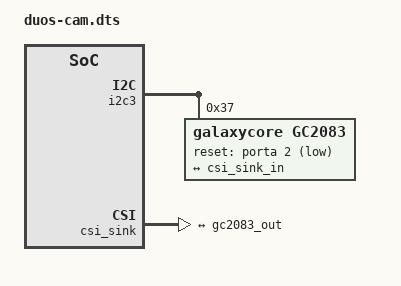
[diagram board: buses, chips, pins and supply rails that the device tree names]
/*
 * GC2083 on J1 of a Milk-V Duo S.
 *
 * Numeric constants rather than dt-bindings macros because neither dtc nor
 * armbian-add-overlay runs the C preprocessor:
 *   147 = CLK_CAM0        (include/dt-bindings/clock/sophgo,cv1800.h)
 *     1 = GPIO_ACTIVE_LOW (include/dt-bindings/gpio/gpio.h)
 * Both are ABI, so this is ugly rather than fragile.
 *
 * The cell counts are not decoration: a fragment has no parent context, so
 * without them dtc reads reg = <0x37> against the default #address-cells = <2>
 * and warns that it is the wrong length.
 *
 * There is no CSI-2 receiver driver for the SG2000, but the endpoint still
 * cannot dangle: fwnode_graph_get_endpoint_by_id() skips any endpoint whose
 * remote is unavailable, and a missing remote counts as unavailable, so the
 * driver would report "missing endpoint node". Hence csi-sink below, which is
 * the far end of the link. duos-cam-stub.ko binds to it and does nothing with
 * the lanes; its only job is to call v4l2_device_register_subdev_nodes() so
 * that /dev/v4l-subdev0 exists. Without that module loaded the node is inert
 * and the sensor still probes - the graph walk only needs the DT node to be
 * present and not disabled.
 *
 * That remote-endpoint is also read by fw_devlink, which turns it into a
 * supplier dependency of the sensor on csi-sink and refuses to probe the sensor
 * until it resolves ("i2c: wait for supplier /csi-sink" in
 * /sys/kernel/debug/devices_deferred). post-init-providers says the dependency
 * does not apply at probe time: parse_post_init_providers carries
 * FWLINK_FLAG_IGNORE, __fwnode_link_add ORs the flag onto the link the graph
 * parser already made, and fwnode_links_check_suppliers then skips it. Both
 * properties have to resolve to the same pair, which they do - the graph parser
 * reduces the endpoint to its port parent (csi-sink) and the consumer to the
 * sensor node.
 *
 * That is not optional even with the compatible present. Without it the sensor
 * waits on the stub, and the stub is a module that may never be loaded; the
 * dependency is also the wrong way round, since it is the stub that waits for
 * the sensor, asynchronously, and the sensor needs nothing from the stub.
 *
 *   dtc -@ -I dts -O dtb -o /boot/overlay-user/duos-cam.dtbo duos-cam.dts
 *   # then user_overlays=duos-cam in /boot/armbianEnv.txt, and reboot
 */

/dts-v1/;
/plugin/;

&i2c3 {
	status = "okay";
	#address-cells = <1>;
	#size-cells = <0>;

	gc2083: sensor@37 {
		compatible = "galaxycore,gc2083";
		reg = <0x37>;

		clocks = <&clk 147>;			/* CLK_CAM0 */
		assigned-clocks = <&clk 147>;
		assigned-clock-rates = <24000000>;

		reset-gpios = <&porta 2 1>;		/* XGPIOA_2, GPIO_ACTIVE_LOW */

		post-init-providers = <&csi_sink>;

		port {
			gc2083_out: endpoint {
				remote-endpoint = <&csi_sink_in>;
				data-lanes = <1 2>;
				link-frequencies = /bits/ 64 <185625000>;
			};
		};
	};
};

&{/} {
	csi_sink: csi-sink {
		compatible = "milkv,duos-cam-stub";

		port {
			csi_sink_in: endpoint {
				remote-endpoint = <&gc2083_out>;
				data-lanes = <1 2>;
			};
		};
	};
};
